# ATA5835 device description
Architecture: AVR8; Family: megaAVR
Registers are 8-bit, access not given, no defined reset value unless marked. A register's access mark holds for its fields unless they carry their own. Offsets are from the block's base; [hi:lo] are bit positions; {n}, {i} and the like mark numbered series; 'fields as' and 'values as' point back to an identical list.

## SSM
Instances: SSM 0x00
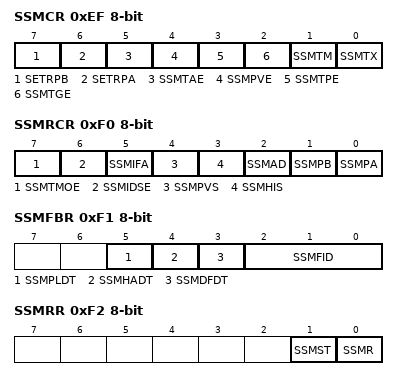
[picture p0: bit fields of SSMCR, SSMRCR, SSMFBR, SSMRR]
0xEF SSMCR — Sequencer State Machine Control Register
  [7] SETRPB — SSM Enable Raw Transparent Path B
  [6] SETRPA — SSM Enable Transparent Path A
  [5] SSMTAE — SSM Tx ASK-Shaping Enable
  [4] SSMPVE — SSM PA Voltage Enable
  [3] SSMTPE — SSM Tx Preemphasis Enable
  [2] SSMTGE — SSM Tx Gauss Shaping Enable
  [1] SSMTM — SSM Temperature Measurement
  [0] SSMTX
0xF0 SSMRCR — Sequencer State Machine Rx Control Register
  [7] SSMTMOE — SSM Transparent Output Enable
  [6] SSMIDSE — SSM ID Check Enable
  [5] SSMIFA — SSM IF Amplifier Enable
  [4] SSMPVS — SSM Path Valid After SOT
  [3] SSMHIS — SSM High Sensitivity Enable
  [2] SSMAD — SSM Antenna Damping Disable
  [1] SSMPB — SSM Path B
  [0] SSMPA — SSM Path A
0xF1 SSMFBR — Sequencer State Machine Filter Bandwidth Register
  [5] SSMPLDT — SSM PLL Lock Delay Time
  [4] SSMHADT — SSM Half Antenna Damping Delay Time
  [3] SSMDFDT — SSM Double Filter Delay Time
  [2:0] SSMFID — SSM Filter Delay
    0=380us (25kHz); 1=202us (50kHz); 2=135us (80kHz); 3=75us (165kHz); 4=58.5us (235kHz); 5=45us (360kHz)
0xF2 SSMRR — Sequencer State Machine Run Register
  [1] SSMST — SSM Stop
  [0] SSMR — SSM Run
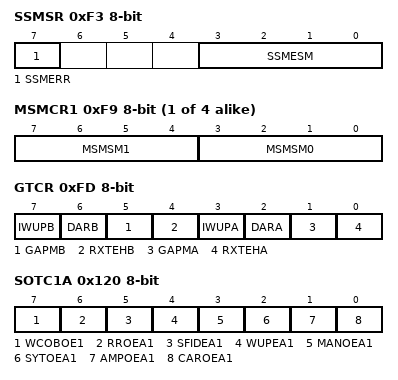
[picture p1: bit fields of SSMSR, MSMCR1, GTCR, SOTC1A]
0xF3 SSMSR — Sequencer State Machine Status Register
  [7] SSMERR — SSM Error
  [3:0] SSMESM — SSM Error State Machine
0xF4 SSMIFR — Sequencer State Machine Interrupt Flag Register
  [0] SSMIF — SSM Interrupt Flag
0xF5 SSMIMR — Sequencer State Machine Interrupt Mask Register
  [0] SSMIM — SSM Interrupt Mask
0xF6 MSMSTR — Master State Machine State Register
  [4:0] SSMMST — Sequencer State Machine Master State
0xF7 SSMSTR — Sequencer State Machine State Register
  [5:0] SSMSTA — SSM State A
0xF8 SSMXSR — Sequencer State Machine Extended State Register
  [5:0] SSMSTB — SSM State B
{0xF8+i} MSMCR{i} (i=1..4) — Master State Machine Control Register {i}
  [7:4] MSMSM{2i-1} — Master State Machine Sub-State Machine Select {2i-1}
    0=None/Stop; 1=PLL en; 2=PLL lock; 3=RX DSP enable; 4=RX DSP disable; 5=TX DSP enable; 6=TX DSP disable; 7=RX to TX; 8=TX to RX; 9=Get telegram; 10=Send telegram; 11=Shut down; 12=VCO Tuning
  [3:0] MSMSM{2i-2} — Master State Machine Sub-State Machine Select {2i-2}
    values as MSMSM{2i-1}
0xFD GTCR — Get Telegram Control Register
  [7] IWUPB — Intermittent WUP Mode Path B
  [6] DARB — Demodulator Automatic Restart Path B
  [5] GAPMB — Gap Mode Path B
  [4] RXTEHB — Rx Telegram End Handling Path B
  [3] IWUPA — Intermittent WUP Mode Path A
  [2] DARA — Demodulator Automatic Restart Path A
  [1] GAPMA — Gap Mode Path A
  [0] RXTEHA — Rx Telegram End Handling Path A
0x120 SOTC1A — Start Of Telegram Conditions 1 Path A
  [7] WCOBOE1 — Wake Check Ok Path B Ok Enable
  [6] RROEA1 — RSSI Range Ok Enable Path A
  [5] SFIDEA1 — Start of Frame Identifier Enable Path A
  [4] WUPEA1 — Wake Up Pattern Enable Path A
  [3] MANOEA1 — Manchester Coding Ok Enable Path A
  [2] SYTOEA1 — Symbol Timing Ok Enable Path A
  [1] AMPOEA1 — Modulation Amplitude Ok Enable Path A
  [0] CAROEA1 — RF Carrier Ok Enable Path A
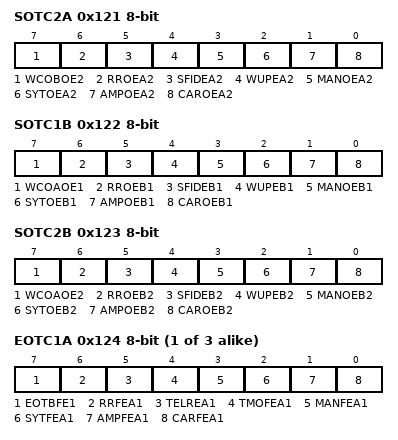
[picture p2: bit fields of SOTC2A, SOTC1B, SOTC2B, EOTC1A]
0x121 SOTC2A — Start Of Telegram Conditions 2 Path A
  [7] WCOBOE2 — Wake Check Ok Path B Ok Enable
  [6] RROEA2 — RSSI Range Ok Enable Path A
  [5] SFIDEA2 — Start of Frame Identifier Enable Path A
  [4] WUPEA2 — Wake Up Pattern Enable Path A
  [3] MANOEA2 — Manchester Coding Ok Enable Path A
  [2] SYTOEA2 — Symbol Timing Ok Enable Path A
  [1] AMPOEA2 — Modulation Amplitude Ok Enable Path A
  [0] CAROEA2 — RF Carrier Ok Enable Path A
0x122 SOTC1B — Start Of Telegram Conditions 1 Path B
  [7] WCOAOE1 — Wake Check Ok Path A Ok Enable
  [6] RROEB1 — RSSI Range Ok Enable Path B
  [5] SFIDEB1 — Start of Frame Identifier Enable Path B
  [4] WUPEB1 — Wake Up Pattern Enable Path B
  [3] MANOEB1 — Manchester Coding Ok Enable Path B
  [2] SYTOEB1 — Symbol Timing Ok Enable Path B
  [1] AMPOEB1 — Modulation Amplitude Ok Enable Path B
  [0] CAROEB1 — RF Carrier Ok Enable Path B
0x123 SOTC2B — Start Of Telegram Conditions 2 Path B
  [7] WCOAOE2 — Wake Check Ok Path A Ok Enable
  [6] RROEB2 — RSSI Range Ok Enable Path B
  [5] SFIDEB2 — Start of Frame Identifier Enable Path B
  [4] WUPEB2 — Wake Up Pattern Enable Path B
  [3] MANOEB2 — Manchester Coding Ok Enable Path B
  [2] SYTOEB2 — Symbol Timing Ok Enable Path B
  [1] AMPOEB2 — Modulation Amplitude Ok Enable Path B
  [0] CAROEB2 — RF Carrier Ok Enable Path B
{0x123+i} EOTC{i}A (i=1..3) — End Of Telegram Conditions {i} Path A
  [7] EOTBFE{i} — End Of Telegram Path B Fail Enable
  [6] RRFEA{i} — RSSI Range Fail Enable Path A
  [5] TELREA{i} — Telegram Length Reached Enable Path A
  [4] TMOFEA{i} — Time-Out Fail Enable Path A
  [3] MANFEA{i} — Manchester Coding Fail Enable Path A
  [2] SYTFEA{i} — Symbol Timing Fail Enable Path A
  [1] AMPFEA{i} — Modulation Amplitude Fail Enable Path A
  [0] CARFEA{i} — RF Carrier Fail Enable Path A
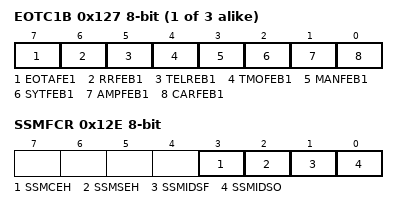
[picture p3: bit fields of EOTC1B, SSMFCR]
{0x126+i} EOTC{i}B (i=1..3) — End Of Telegram Conditions {i} Path B
  [7] EOTAFE{i} — End Of Telegram Path A Fail Enable
  [6] RRFEB{i} — RSSI Range Fail Enable Path B
  [5] TELREB{i} — Telegram Length Reached Enable Path B
  [4] TMOFEB{i} — Time-Out Fail Enable Path B
  [3] MANFEB{i} — Manchester Coding Fail Enable Path B
  [2] SYTFEB{i} — Symbol Timing Fail Enable Path B
  [1] AMPFEB{i} — Modulation Amplitude Fail Enable Path B
  [0] CARFEB{i} — RF Carrier Fail Enable Path B
0x12A WCOTOA — Wake Check Ok Time-Out Path A
0x12B WCOTOB — Wake Check Ok Time-Out Path B
0x12C SOTTOA — Start Of Telegram Time Out Path A
0x12D SOTTOB — Start Of Telegram Time Out Path B
0x12E SSMFCR — Sequencer State Machine Flow Control Register
  [3] SSMCEH — SSM Continuous Start Telegram End Handling
  [2] SSMSEH — SSM Single Start Telegram End Handling
  [1] SSMIDSF — SSM ID Scan Fail
  [0] SSMIDSO — SSM ID Scan OK
